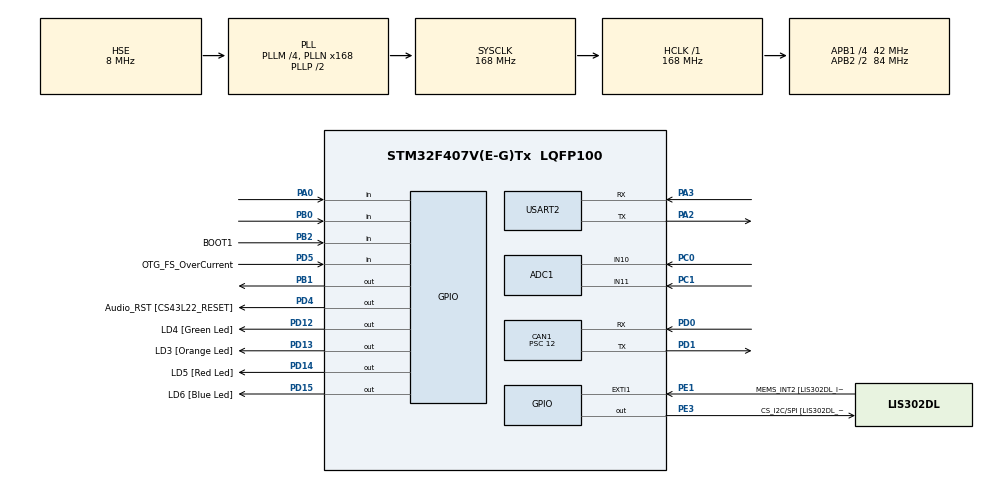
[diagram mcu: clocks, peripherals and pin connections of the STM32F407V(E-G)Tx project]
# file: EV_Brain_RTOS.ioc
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ADC1.Channel-0\#ChannelRegularConversion=ADC_CHANNEL_10
ADC1.Channel-1\#ChannelRegularConversion=ADC_CHANNEL_11
ADC1.ContinuousConvMode=ENABLE
ADC1.EOCSelection=ADC_EOC_SINGLE_CONV
ADC1.InjNumberOfConversion=0
ADC1.NbrOfConversion=2
ADC1.NbrOfConversionFlag=1
ADC1.Rank-0\#ChannelRegularConversion=1
ADC1.Rank-1\#ChannelRegularConversion=2
ADC1.SamplingTime-0\#ChannelRegularConversion=ADC_SAMPLETIME_15CYCLES
ADC1.SamplingTime-1\#ChannelRegularConversion=ADC_SAMPLETIME_15CYCLES
ADC1.master=1
CAN1.BS1=CAN_BS1_11TQ
CAN1.BS2=CAN_BS2_2TQ
CAN1.CalculateBaudRate=250000
CAN1.CalculateTimeBit=4000
CAN1.CalculateTimeQuantum=285.7142857142857
CAN1.Prescaler=12
Mcu.Family=STM32F4
Mcu.Name=STM32F407V(E-G)Tx
Mcu.Package=LQFP100
NVIC.CAN1_RX0_IRQn=true\:0\:0\:false\:false\:true\:true\:true\:true
NVIC.PriorityGroup=NVIC_PRIORITYGROUP_4
PA0-WKUP.GPIO_PuPd=GPIO_PULLDOWN
PA0-WKUP.Signal=GPIO_Input
PA13.GPIO_Label=SWDIO
PA13.Mode=Serial_Wire
PA13.Signal=SYS_JTMS-SWDIO
PA14.GPIO_Label=SWCLK
PA14.Mode=Serial_Wire
PA14.Signal=SYS_JTCK-SWCLK
PA2.Mode=Asynchronous
PA2.Signal=USART2_TX
PA3.Mode=Asynchronous
PA3.Signal=USART2_RX
PB0.GPIO_PuPd=GPIO_PULLUP
PB0.Signal=GPIO_Input
PB1.GPIO_ModeDefaultOutputPP=GPIO_MODE_OUTPUT_PP
PB1.GPIO_PuPd=GPIO_PULLDOWN
PB1.PinState=GPIO_PIN_RESET
PB1.Signal=GPIO_Output
PB2.GPIO_Label=BOOT1
PB2.GPIO_Mode=GPIO_MODE_INPUT
PB2.GPIO_PuPd=GPIO_NOPULL
PB2.Signal=GPIO_Input
PC0.Signal=ADCx_IN10
PC1.Signal=ADCx_IN11
PC14-OSC32_IN.GPIO_Label=PC14-OSC32_IN
PC14-OSC32_IN.Mode=LSE-External-Oscillator
PC14-OSC32_IN.Signal=RCC_OSC32_IN
PC15-OSC32_OUT.GPIO_Label=PC15-OSC32_OUT
PC15-OSC32_OUT.Mode=LSE-External-Oscillator
PC15-OSC32_OUT.Signal=RCC_OSC32_OUT
PD0.Mode=CAN_Activate
PD0.Signal=CAN1_RX
PD1.Mode=CAN_Activate
PD1.Signal=CAN1_TX
PD12.GPIO_Label=LD4 [Green Led]
PD12.GPIO_PuPd=GPIO_NOPULL
PD12.GPIO_Speed=GPIO_SPEED_FREQ_LOW
PD12.Signal=GPIO_Output
PD13.GPIO_Label=LD3 [Orange Led]
PD13.GPIO_PuPd=GPIO_NOPULL
PD13.GPIO_Speed=GPIO_SPEED_FREQ_LOW
PD13.Signal=GPIO_Output
PD14.GPIO_Label=LD5 [Red Led]
PD14.GPIO_PuPd=GPIO_NOPULL
PD14.GPIO_Speed=GPIO_SPEED_FREQ_LOW
PD14.Signal=GPIO_Output
PD15.GPIO_Label=LD6 [Blue Led]
PD15.GPIO_PuPd=GPIO_NOPULL
PD15.GPIO_Speed=GPIO_SPEED_FREQ_LOW
PD15.Signal=GPIO_Output
PD4.GPIO_Label=Audio_RST [CS43L22_RESET]
PD4.GPIO_PuPd=GPIO_NOPULL
PD4.GPIO_Speed=GPIO_SPEED_FREQ_LOW
PD4.Signal=GPIO_Output
PD5.GPIO_Label=OTG_FS_OverCurrent
PD5.GPIO_Mode=GPIO_MODE_INPUT
PD5.GPIO_PuPd=GPIO_NOPULL
PD5.Signal=GPIO_Input
PE1.GPIO_Label=MEMS_INT2 [LIS302DL_INT2]
PE1.GPIO_ModeDefaultEXTI=GPIO_MODE_EVT_RISING
PE1.GPIO_PuPd=GPIO_NOPULL
PE1.Signal=GPXTI1
PE3.GPIO_Label=CS_I2C/SPI [LIS302DL_CS_I2C/SPI]
PE3.GPIO_PuPd=GPIO_NOPULL
PE3.GPIO_Speed=GPIO_SPEED_FREQ_LOW
PE3.Signal=GPIO_Output
PH0-OSC_IN.GPIO_Label=PH0-OSC_IN
PH0-OSC_IN.Mode=HSE-External-Oscillator
PH0-OSC_IN.Signal=RCC_OSC_IN
PH1-OSC_OUT.GPIO_Label=PH1-OSC_OUT
PH1-OSC_OUT.Mode=HSE-External-Oscillator
PH1-OSC_OUT.Signal=RCC_OSC_OUT
ProjectManager.HeapSize=0x200
ProjectManager.StackSize=0x400
ProjectManager.TargetToolchain=STM32CubeIDE
RCC.48MHZClocksFreq_Value=48000000
RCC.AHBFreq_Value=168000000
RCC.APB1CLKDivider=RCC_HCLK_DIV4
RCC.APB1Freq_Value=42000000
RCC.APB1TimFreq_Value=84000000
RCC.APB2CLKDivider=RCC_HCLK_DIV2
RCC.APB2Freq_Value=84000000
RCC.APB2TimFreq_Value=168000000
RCC.CortexFreq_Value=168000000
RCC.HCLKFreq_Value=168000000
RCC.HSE_VALUE=8000000
RCC.HSI_VALUE=16000000
RCC.PLLM=4
RCC.PLLN=168
RCC.PLLQ=7
RCC.PLLSourceVirtual=RCC_PLLSOURCE_HSE
RCC.SYSCLKFreq_VALUE=168000000
RCC.SYSCLKSource=RCC_SYSCLKSOURCE_PLLCLK
RCC.VCOOutputFreq_Value=336000000
SH.ADCx_IN10.0=ADC1_IN10,IN10
SH.ADCx_IN11.0=ADC1_IN11,IN11
USART2.VirtualMode=VM_ASYNC
board=STM32F407G-DISC1

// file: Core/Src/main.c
/* USER CODE BEGIN Header */
/**
 ******************************************************************************
 * @file           : main.c
 * @brief          : Main program body
 ******************************************************************************
 * @attention
 *
 * <h2><center>&copy; Copyright (c) 2020 STMicroelectronics.
 * All rights reserved.</center></h2>
 *
 * This software component is licensed by ST under Ultimate Liberty license
 * SLA0044, the "License"; You may not use this file except in compliance with
 * the License. You may obtain a copy of the License at:
 *                             www.st.com/SLA0044
 *
 ******************************************************************************
 */
/* USER CODE END Header */
#include "main.h"

/* USER CODE BEGIN Includes */
#include "program.h"

/* USER CODE END Includes */

 ADC_HandleTypeDef hadc1;

CAN_HandleTypeDef hcan1;

UART_HandleTypeDef huart2;

void SystemClock_Config(void);
static void MX_GPIO_Init(void);
static void MX_ADC1_Init(void);
static void MX_USART2_UART_Init(void);
static void MX_CAN1_Init(void);

int main(void)
{

  /* MCU Configuration--------------------------------------------------------*/

  /* Reset of all peripherals, Initializes the Flash interface and the Systick. */
  HAL_Init();

  /* Configure the system clock */
  SystemClock_Config();

  /* Initialize all configured peripherals */
  MX_GPIO_Init();
  MX_ADC1_Init();
  MX_USART2_UART_Init();
  MX_CAN1_Init();
  /* USER CODE BEGIN 2 */
	// If we call program() here it we should never execute the code below
	program();
  /* USER CODE END 2 */

  /* Infinite loop */

}

void SystemClock_Config(void)
{
  RCC_OscInitTypeDef RCC_OscInitStruct = {0};
  RCC_ClkInitTypeDef RCC_ClkInitStruct = {0};

  /** Configure the main internal regulator output voltage
  */
  __HAL_RCC_PWR_CLK_ENABLE();
  __HAL_PWR_VOLTAGESCALING_CONFIG(PWR_REGULATOR_VOLTAGE_SCALE1);

  /** Initializes the RCC Oscillators according to the specified parameters
  * in the RCC_OscInitTypeDef structure.
  */
  RCC_OscInitStruct.OscillatorType = RCC_OSCILLATORTYPE_HSE;
  RCC_OscInitStruct.HSEState = RCC_HSE_ON;
  RCC_OscInitStruct.PLL.PLLState = RCC_PLL_ON;
  RCC_OscInitStruct.PLL.PLLSource = RCC_PLLSOURCE_HSE;
  RCC_OscInitStruct.PLL.PLLM = 4;
  RCC_OscInitStruct.PLL.PLLN = 168;
  RCC_OscInitStruct.PLL.PLLP = RCC_PLLP_DIV2;
  RCC_OscInitStruct.PLL.PLLQ = 7;
  if (HAL_RCC_OscConfig(&RCC_OscInitStruct) != HAL_OK)
  {
    Error_Handler();
  }

  /** Initializes the CPU, AHB and APB buses clocks
  */
  RCC_ClkInitStruct.ClockType = RCC_CLOCKTYPE_HCLK|RCC_CLOCKTYPE_SYSCLK
                              |RCC_CLOCKTYPE_PCLK1|RCC_CLOCKTYPE_PCLK2;
  RCC_ClkInitStruct.SYSCLKSource = RCC_SYSCLKSOURCE_PLLCLK;
  RCC_ClkInitStruct.AHBCLKDivider = RCC_SYSCLK_DIV1;
  RCC_ClkInitStruct.APB1CLKDivider = RCC_HCLK_DIV4;
  RCC_ClkInitStruct.APB2CLKDivider = RCC_HCLK_DIV2;

  if (HAL_RCC_ClockConfig(&RCC_ClkInitStruct, FLASH_LATENCY_5) != HAL_OK)
  {
    Error_Handler();
  }
}

static void MX_ADC1_Init(void)
{

  ADC_ChannelConfTypeDef sConfig = {0};

  /** Configure the global features of the ADC (Clock, Resolution, Data Alignment and number of conversion)
  */
  hadc1.Instance = ADC1;
  hadc1.Init.ClockPrescaler = ADC_CLOCK_SYNC_PCLK_DIV4;
  hadc1.Init.Resolution = ADC_RESOLUTION_12B;
  hadc1.Init.ScanConvMode = ENABLE;
  hadc1.Init.ContinuousConvMode = ENABLE;
  hadc1.Init.DiscontinuousConvMode = DISABLE;
  hadc1.Init.ExternalTrigConvEdge = ADC_EXTERNALTRIGCONVEDGE_NONE;
  hadc1.Init.ExternalTrigConv = ADC_SOFTWARE_START;
  hadc1.Init.DataAlign = ADC_DATAALIGN_RIGHT;
  hadc1.Init.NbrOfConversion = 2;
  hadc1.Init.DMAContinuousRequests = DISABLE;
  hadc1.Init.EOCSelection = ADC_EOC_SINGLE_CONV;
  if (HAL_ADC_Init(&hadc1) != HAL_OK)
  {
    Error_Handler();
  }

  /** Configure for the selected ADC regular channel its corresponding rank in the sequencer and its sample time.
  */
  sConfig.Channel = ADC_CHANNEL_10;
  sConfig.Rank = 1;
  sConfig.SamplingTime = ADC_SAMPLETIME_15CYCLES;
  if (HAL_ADC_ConfigChannel(&hadc1, &sConfig) != HAL_OK)
  {
    Error_Handler();
  }

  /** Configure for the selected ADC regular channel its corresponding rank in the sequencer and its sample time.
  */
  sConfig.Channel = ADC_CHANNEL_11;
  sConfig.Rank = 2;
  if (HAL_ADC_ConfigChannel(&hadc1, &sConfig) != HAL_OK)
  {
    Error_Handler();
  }

}

static void MX_CAN1_Init(void)
{

  hcan1.Instance = CAN1;
  hcan1.Init.Prescaler = 12;
  hcan1.Init.Mode = CAN_MODE_NORMAL;
  hcan1.Init.SyncJumpWidth = CAN_SJW_1TQ;
  hcan1.Init.TimeSeg1 = CAN_BS1_11TQ;
  hcan1.Init.TimeSeg2 = CAN_BS2_2TQ;
  hcan1.Init.TimeTriggeredMode = DISABLE;
  hcan1.Init.AutoBusOff = DISABLE;
  hcan1.Init.AutoWakeUp = DISABLE;
  hcan1.Init.AutoRetransmission = DISABLE;
  hcan1.Init.ReceiveFifoLocked = DISABLE;
  hcan1.Init.TransmitFifoPriority = DISABLE;
  if (HAL_CAN_Init(&hcan1) != HAL_OK)
  {
    Error_Handler();
  }

}

static void MX_USART2_UART_Init(void)
{

  huart2.Instance = USART2;
  huart2.Init.BaudRate = 115200;
  huart2.Init.WordLength = UART_WORDLENGTH_8B;
  huart2.Init.StopBits = UART_STOPBITS_1;
  huart2.Init.Parity = UART_PARITY_NONE;
  huart2.Init.Mode = UART_MODE_TX_RX;
  huart2.Init.HwFlowCtl = UART_HWCONTROL_NONE;
  huart2.Init.OverSampling = UART_OVERSAMPLING_16;
  if (HAL_UART_Init(&huart2) != HAL_OK)
  {
    Error_Handler();
  }

}

static void MX_GPIO_Init(void)
{
  GPIO_InitTypeDef GPIO_InitStruct = {0};

  /* GPIO Ports Clock Enable */
  __HAL_RCC_GPIOE_CLK_ENABLE();
  __HAL_RCC_GPIOC_CLK_ENABLE();
  __HAL_RCC_GPIOH_CLK_ENABLE();
  __HAL_RCC_GPIOA_CLK_ENABLE();
  __HAL_RCC_GPIOB_CLK_ENABLE();
  __HAL_RCC_GPIOD_CLK_ENABLE();

  /*Configure GPIO pin Output Level */
  HAL_GPIO_WritePin(CS_I2C_SPI_GPIO_Port, CS_I2C_SPI_Pin, GPIO_PIN_RESET);

  /*Configure GPIO pin Output Level */
  HAL_GPIO_WritePin(GPIOB, GPIO_PIN_1, GPIO_PIN_RESET);

  /*Configure GPIO pin Output Level */
  HAL_GPIO_WritePin(GPIOD, LD4_Pin|LD3_Pin|LD5_Pin|LD6_Pin
                          |Audio_RST_Pin, GPIO_PIN_RESET);

  /*Configure GPIO pin : CS_I2C_SPI_Pin */
  GPIO_InitStruct.Pin = CS_I2C_SPI_Pin;
  GPIO_InitStruct.Mode = GPIO_MODE_OUTPUT_PP;
  GPIO_InitStruct.Pull = GPIO_NOPULL;
  GPIO_InitStruct.Speed = GPIO_SPEED_FREQ_LOW;
  HAL_GPIO_Init(CS_I2C_SPI_GPIO_Port, &GPIO_InitStruct);

  /*Configure GPIO pin : PA0 */
  GPIO_InitStruct.Pin = GPIO_PIN_0;
  GPIO_InitStruct.Mode = GPIO_MODE_INPUT;
  GPIO_InitStruct.Pull = GPIO_PULLDOWN;
  HAL_GPIO_Init(GPIOA, &GPIO_InitStruct);

  /*Configure GPIO pin : PB0 */
  GPIO_InitStruct.Pin = GPIO_PIN_0;
  GPIO_InitStruct.Mode = GPIO_MODE_INPUT;
  GPIO_InitStruct.Pull = GPIO_PULLUP;
  HAL_GPIO_Init(GPIOB, &GPIO_InitStruct);

  /*Configure GPIO pin : PB1 */
  GPIO_InitStruct.Pin = GPIO_PIN_1;
  GPIO_InitStruct.Mode = GPIO_MODE_OUTPUT_PP;
  GPIO_InitStruct.Pull = GPIO_PULLDOWN;
  GPIO_InitStruct.Speed = GPIO_SPEED_FREQ_LOW;
  HAL_GPIO_Init(GPIOB, &GPIO_InitStruct);

  /*Configure GPIO pin : BOOT1_Pin */
  GPIO_InitStruct.Pin = BOOT1_Pin;
  GPIO_InitStruct.Mode = GPIO_MODE_INPUT;
  GPIO_InitStruct.Pull = GPIO_NOPULL;
  HAL_GPIO_Init(BOOT1_GPIO_Port, &GPIO_InitStruct);

  /*Configure GPIO pins : LD4_Pin LD3_Pin LD5_Pin LD6_Pin
                           Audio_RST_Pin */
  GPIO_InitStruct.Pin = LD4_Pin|LD3_Pin|LD5_Pin|LD6_Pin
                          |Audio_RST_Pin;
  GPIO_InitStruct.Mode = GPIO_MODE_OUTPUT_PP;
  GPIO_InitStruct.Pull = GPIO_NOPULL;
  GPIO_InitStruct.Speed = GPIO_SPEED_FREQ_LOW;
  HAL_GPIO_Init(GPIOD, &GPIO_InitStruct);

  /*Configure GPIO pin : OTG_FS_OverCurrent_Pin */
  GPIO_InitStruct.Pin = OTG_FS_OverCurrent_Pin;
  GPIO_InitStruct.Mode = GPIO_MODE_INPUT;
  GPIO_InitStruct.Pull = GPIO_NOPULL;
  HAL_GPIO_Init(OTG_FS_OverCurrent_GPIO_Port, &GPIO_InitStruct);

  /*Configure GPIO pin : MEMS_INT2_Pin */
  GPIO_InitStruct.Pin = MEMS_INT2_Pin;
  GPIO_InitStruct.Mode = GPIO_MODE_EVT_RISING;
  GPIO_InitStruct.Pull = GPIO_NOPULL;
  HAL_GPIO_Init(MEMS_INT2_GPIO_Port, &GPIO_InitStruct);

}

void Error_Handler(void)
{
}
